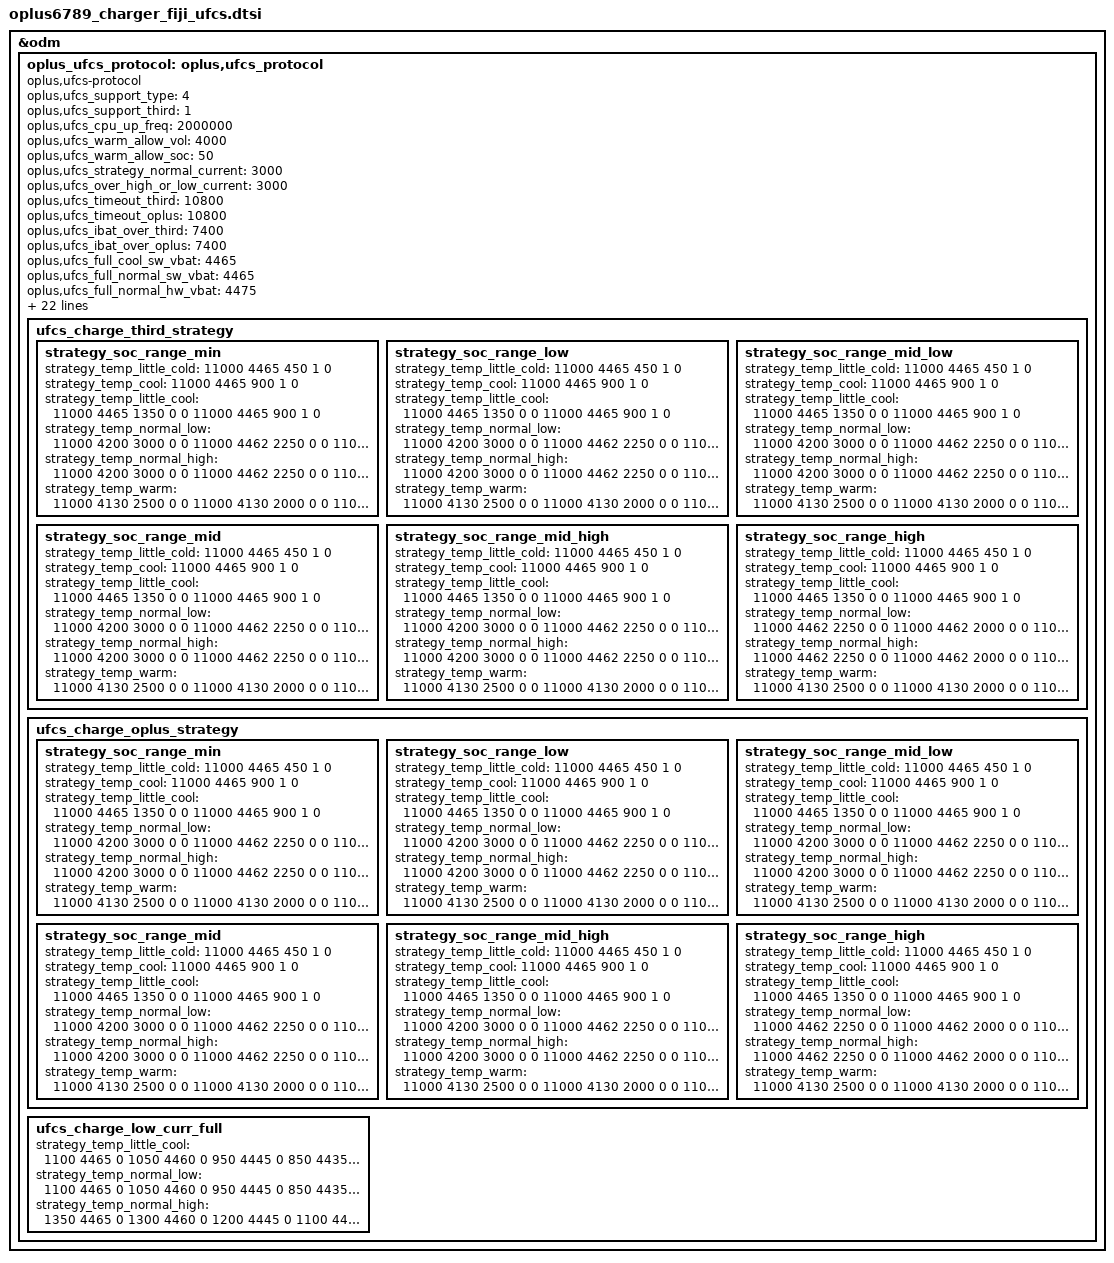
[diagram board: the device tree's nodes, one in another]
&odm {
	oplus_ufcs_protocol: oplus,ufcs_protocol {
		status = "ok";
		compatible = "oplus,ufcs-protocol";
	};
};

&oplus_ufcs_protocol {
	oplus,ufcs_support_type = <4>;
	oplus,ufcs_support_third = <1>;
	oplus,ufcs_cpu_up_freq = <2000000>;
	oplus,ufcs_warm_allow_vol = <4000>;
	oplus,ufcs_warm_allow_soc = <50>;
	oplus,ufcs_strategy_normal_current = <3000>;
	oplus,ufcs_over_high_or_low_current = <3000>;
	oplus,ufcs_timeout_third = <10800>;
	oplus,ufcs_timeout_oplus = <10800>;
	oplus,ufcs_ibat_over_third = <7400>;
	oplus,ufcs_ibat_over_oplus = <7400>;
	oplus,ufcs_full_cool_sw_vbat = <4465>;
	oplus,ufcs_full_normal_sw_vbat = <4465>;
	oplus,ufcs_full_normal_hw_vbat = <4475>;
	oplus,ufcs_full_ffc_vbat = <4465>;
	oplus,ufcs_full_warm_vbat = <4130>;
	oplus,ufcs_full_cool_sw_vbat_third = <4465>;
	oplus,ufcs_full_normal_sw_vbat_third= <4465>;
	oplus,ufcs_full_normal_hw_vbat_third = <4475>;
	oplus,ufcs_freq_mincore = <968000>;
	oplus,ufcs_freq_midcore = <1418000>;
	oplus,ufcs_freq_maxcore = <1418000>;
	oplus,ufcs_current_change_timeout = <100>;
	oplus,ufcs_r_default = <270 45 10 45 20 20 20>;
	oplus,ufcs_rmos_mohm = <5>;
	oplus,ufcs_r_limit = <150 80 70 50 30>;
	oplus,ufcs_strategy_batt_high_temp = <400 420 430 390 410 420>;
	oplus,ufcs_strategy_high_current = <3000 2000 2000 3000 3000 3000>;
	oplus,ufcs_charge_strategy_soc = <0 20 35 55 75 85 95>;
	oplus,ufcs_charge_strategy_temp = <50 50 120 160 350 440 530>;
	oplus,ufcs_low_curr_full_strategy_temp = <120 200 350 440>;

	ufcs_charge_third_strategy {
		strategy_soc_range_min {
			strategy_temp_little_cold =	<11000 4465  450 1 0>;
			strategy_temp_cool =		<11000 4465  900 1 0>;
			strategy_temp_little_cool =	<11000 4465 1350 0 0
							 11000 4465  900 1 0>;
			strategy_temp_normal_low =	<11000 4200 3000 0 0
							 11000 4462 2250 0 0
							 11000 4462 2000 0 0
							 11000 4462 1500 0 0
							 11000 4465 1000 1 0>;
			strategy_temp_normal_high =	<11000 4200 3000 0 0
							 11000 4462 2250 0 0
							 11000 4462 2000 0 0
							 11000 4462 1500 0 0
							 11000 4465 1000 1 0>;
			strategy_temp_warm =		<11000 4130 2500 0 0
							 11000 4130 2000 0 0
							 11000 4130 1500 0 0
							 11000 4130 1000 1 0>;
		};
		strategy_soc_range_low {
			strategy_temp_little_cold =	<11000 4465  450 1 0>;
			strategy_temp_cool =		<11000 4465  900 1 0>;
			strategy_temp_little_cool =	<11000 4465 1350 0 0
							 11000 4465  900 1 0>;
			strategy_temp_normal_low =	<11000 4200 3000 0 0
							 11000 4462 2250 0 0
							 11000 4462 2000 0 0
							 11000 4462 1500 0 0
							 11000 4465 1000 1 0>;
			strategy_temp_normal_high =	<11000 4200 3000 0 0
							 11000 4462 2250 0 0
							 11000 4462 2000 0 0
							 11000 4462 1500 0 0
							 11000 4465 1000 1 0>;
			strategy_temp_warm =		<11000 4130 2500 0 0
							 11000 4130 2000 0 0
							 11000 4130 1500 0 0
							 11000 4130 1000 1 0>;
		};
		strategy_soc_range_mid_low {
			strategy_temp_little_cold =	<11000 4465  450 1 0>;
			strategy_temp_cool =		<11000 4465  900 1 0>;
			strategy_temp_little_cool =	<11000 4465 1350 0 0
							 11000 4465  900 1 0>;
			strategy_temp_normal_low =	<11000 4200 3000 0 0
							 11000 4462 2250 0 0
							 11000 4462 2000 0 0
							 11000 4462 1500 0 0
							 11000 4465 1000 1 0>;
			strategy_temp_normal_high =	<11000 4200 3000 0 0
							 11000 4462 2250 0 0
							 11000 4462 2000 0 0
							 11000 4462 1500 0 0
							 11000 4465 1000 1 0>;
			strategy_temp_warm =		<11000 4130 2500 0 0
							 11000 4130 2000 0 0
							 11000 4130 1500 0 0
							 11000 4130 1000 1 0>;
		};
		strategy_soc_range_mid {
			strategy_temp_little_cold =	<11000 4465  450 1 0>;
			strategy_temp_cool =		<11000 4465  900 1 0>;
			strategy_temp_little_cool =	<11000 4465 1350 0 0
							 11000 4465  900 1 0>;
			strategy_temp_normal_low =	<11000 4200 3000 0 0
							 11000 4462 2250 0 0
							 11000 4462 2000 0 0
							 11000 4462 1500 0 0
							 11000 4465 1000 1 0>;
			strategy_temp_normal_high =	<11000 4200 3000 0 0
							 11000 4462 2250 0 0
							 11000 4462 2000 0 0
							 11000 4462 1500 0 0
							 11000 4465 1000 1 0>;
			strategy_temp_warm =		<11000 4130 2500 0 0
							 11000 4130 2000 0 0
							 11000 4130 1500 0 0
							 11000 4130 1000 1 0>;
		};
		strategy_soc_range_mid_high {
			strategy_temp_little_cold =	<11000 4465  450 1 0>;
			strategy_temp_cool =		<11000 4465  900 1 0>;
			strategy_temp_little_cool =	<11000 4465 1350 0 0
							 11000 4465  900 1 0>;
			strategy_temp_normal_low =	<11000 4200 3000 0 0
							 11000 4462 2250 0 0
							 11000 4462 2000 0 0
							 11000 4462 1500 0 0
							 11000 4465 1000 1 0>;
			strategy_temp_normal_high =	<11000 4200 3000 0 0
							 11000 4462 2250 0 0
							 11000 4462 2000 0 0
							 11000 4462 1500 0 0
							 11000 4465 1000 1 0>;
			strategy_temp_warm =		<11000 4130 2500 0 0
							 11000 4130 2000 0 0
							 11000 4130 1500 0 0
							 11000 4130 1000 1 0>;
		};
		strategy_soc_range_high {
			strategy_temp_little_cold =	<11000 4465  450 1 0>;
			strategy_temp_cool =		<11000 4465  900 1 0>;
			strategy_temp_little_cool =	<11000 4465 1350 0 0
							 11000 4465  900 1 0>;
			strategy_temp_normal_low =	<11000 4462 2250 0 0
							 11000 4462 2000 0 0
							 11000 4462 1500 0 0
							 11000 4465 1000 1 0>;
			strategy_temp_normal_high =	<11000 4462 2250 0 0
							 11000 4462 2000 0 0
							 11000 4462 1500 0 0
							 11000 4465 1000 1 0>;
			strategy_temp_warm =		<11000 4130 2500 0 0
							 11000 4130 2000 0 0
							 11000 4130 1500 0 0
							 11000 4130 1000 1 0>;
		};
	};
	ufcs_charge_oplus_strategy {
		strategy_soc_range_min {
			strategy_temp_little_cold =	<11000 4465  450 1 0>;
			strategy_temp_cool =		<11000 4465  900 1 0>;
			strategy_temp_little_cool =	<11000 4465 1350 0 0
							 11000 4465  900 1 0>;
			strategy_temp_normal_low =	<11000 4200 3000 0 0
							 11000 4462 2250 0 0
							 11000 4462 2000 0 0
							 11000 4462 1500 0 0
							 11000 4465 1000 1 0>;
			strategy_temp_normal_high =	<11000 4200 3000 0 0
							 11000 4462 2250 0 0
							 11000 4462 2000 0 0
							 11000 4462 1500 0 0
							 11000 4465 1000 1 0>;
			strategy_temp_warm =		<11000 4130 2500 0 0
							 11000 4130 2000 0 0
							 11000 4130 1500 0 0
							 11000 4130 1000 1 0>;
		};
		strategy_soc_range_low {
			strategy_temp_little_cold =	<11000 4465  450 1 0>;
			strategy_temp_cool =		<11000 4465  900 1 0>;
			strategy_temp_little_cool =	<11000 4465 1350 0 0
							 11000 4465  900 1 0>;
			strategy_temp_normal_low =	<11000 4200 3000 0 0
							 11000 4462 2250 0 0
							 11000 4462 2000 0 0
							 11000 4462 1500 0 0
							 11000 4465 1000 1 0>;
			strategy_temp_normal_high =	<11000 4200 3000 0 0
							 11000 4462 2250 0 0
							 11000 4462 2000 0 0
							 11000 4462 1500 0 0
							 11000 4465 1000 1 0>;
			strategy_temp_warm =		<11000 4130 2500 0 0
							 11000 4130 2000 0 0
							 11000 4130 1500 0 0
							 11000 4130 1000 1 0>;
		};
		strategy_soc_range_mid_low {
			strategy_temp_little_cold =	<11000 4465  450 1 0>;
			strategy_temp_cool =		<11000 4465  900 1 0>;
			strategy_temp_little_cool =	<11000 4465 1350 0 0
							 11000 4465  900 1 0>;
			strategy_temp_normal_low =	<11000 4200 3000 0 0
							 11000 4462 2250 0 0
							 11000 4462 2000 0 0
							 11000 4462 1500 0 0
							 11000 4465 1000 1 0>;
			strategy_temp_normal_high =	<11000 4200 3000 0 0
							 11000 4462 2250 0 0
							 11000 4462 2000 0 0
							 11000 4462 1500 0 0
							 11000 4465 1000 1 0>;
			strategy_temp_warm =		<11000 4130 2500 0 0
							 11000 4130 2000 0 0
							 11000 4130 1500 0 0
							 11000 4130 1000 1 0>;
		};
		strategy_soc_range_mid {
			strategy_temp_little_cold =	<11000 4465  450 1 0>;
			strategy_temp_cool =		<11000 4465  900 1 0>;
			strategy_temp_little_cool =	<11000 4465 1350 0 0
							 11000 4465 900 1 0>;
			strategy_temp_normal_low =	<11000 4200 3000 0 0
							 11000 4462 2250 0 0
							 11000 4462 2000 0 0
							 11000 4462 1500 0 0
							 11000 4465 1000 1 0>;
			strategy_temp_normal_high =	<11000 4200 3000 0 0
							 11000 4462 2250 0 0
							 11000 4462 2000 0 0
							 11000 4462 1500 0 0
							 11000 4465 1000 1 0>;
			strategy_temp_warm =		<11000 4130 2500 0 0
							 11000 4130 2000 0 0
							 11000 4130 1500 0 0
							 11000 4130 1000 1 0>;
		};
		strategy_soc_range_mid_high {
			strategy_temp_little_cold =	<11000 4465  450 1 0>;
			strategy_temp_cool =		<11000 4465  900 1 0>;
			strategy_temp_little_cool =	<11000 4465 1350 0 0
							 11000 4465  900 1 0>;
			strategy_temp_normal_low =	<11000 4200 3000 0 0
							 11000 4462 2250 0 0
							 11000 4462 2000 0 0
							 11000 4462 1500 0 0
							 11000 4465 1000 1 0>;
			strategy_temp_normal_high =	<11000 4200 3000 0 0
							 11000 4462 2250 0 0
							 11000 4462 2000 0 0
							 11000 4462 1500 0 0
							 11000 4465 1000 1 0>;
			strategy_temp_warm =		<11000 4130 2500 0 0
							 11000 4130 2000 0 0
							 11000 4130 1500 0 0
							 11000 4130 1000 1 0>;
		};
		strategy_soc_range_high {
			strategy_temp_little_cold =	<11000 4465  450 1 0>;
			strategy_temp_cool =		<11000 4465  900 1 0>;
			strategy_temp_little_cool =	<11000 4465 1350 0 0
							 11000 4465  900 1 0>;
			strategy_temp_normal_low =	<11000 4462 2250 0 0
							 11000 4462 2000 0 0
							 11000 4462 1500 0 0
							 11000 4465 1000 1 0>;
			strategy_temp_normal_high =	<11000 4462 2250 0 0
							 11000 4462 2000 0 0
							 11000 4462 1500 0 0
							 11000 4465 1000 1 0>;
			strategy_temp_warm =		<11000 4130 2500 0 0
							 11000 4130 2000 0 0
							 11000 4130 1500 0 0
							 11000 4130 1000 1 0>;
		};
	};
	ufcs_charge_low_curr_full {
		strategy_temp_little_cool = 	<1100 4465 0
						 1050 4460 0
						 950  4445 0
						 850  4435 0
						 700  4425 1>;
		strategy_temp_normal_low =	<1100 4465 0
						 1050 4460 0
						 950  4445 0
						 850  4435 0
						 700  4425 1>;
		strategy_temp_normal_high = 	<1350 4465 0
						 1300 4460 0
						 1200 4445 0
						 1100 4435 0
						 950  4425 1>;
	};
};
